# HWSEQ_L3_MAIN register map
Vendor: Texas Instruments
Peripheral module from a debugger description file (folder omap5430_ES2_PUBLIC).
Registers are 32-bit, access per field, reset 0x0 unless marked. A register's access mark holds for its fields unless they carry their own. Offsets are as the file gives them; lines under a group give offsets from that group; [hi:lo] are bit positions; {n}, {i} and the like mark numbered series; 'fields as' and 'values as' point back to an identical list; <NAME> marks a mode.

## HWSEQ_L3_MAIN
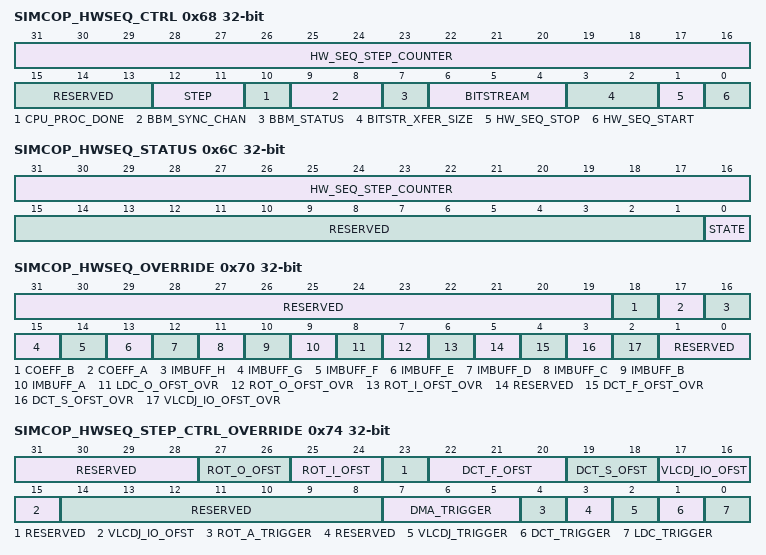
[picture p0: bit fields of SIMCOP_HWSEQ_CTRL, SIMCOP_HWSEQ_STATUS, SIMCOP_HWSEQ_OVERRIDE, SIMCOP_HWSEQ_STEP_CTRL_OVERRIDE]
0x68 SIMCOP_HWSEQ_CTRL — SIMCOP HW sequencer control register
  [31:16] HW_SEQ_STEP_COUNTER rw — Number of steps executed by the HW sequencer. HW_SEQ_STEP_COUNTER=0 corresponds to manual sequencing.
  [15:13] RESERVED ro — Read returns 0.
  [12:11] STEP rw — This register is automatically updated by the HW sequencer when it is active. Otherwise, SW could use it to activate the content of a given set of step registers (SIMCOP_HWSEQ_STEP_i).
  [10] CPU_PROC_DONE wo — Used by the CPU to tell that it has completed data processing. This feature should be used together with the CPU_PROC_START_IRQ event Read's always return 0.
    0=No_effect; 1=CPU_processing_completed
  [9:8] BBM_SYNC_CHAN rw — Defines the SIMCOP DMA HW synchronization channel to be used for BBM. This register is only used when BITSTREAM=ENCODE or DECODE. SW must ensure that the same DMA HW synchronization channel isn't used by the HW sequencer.
  [7] BBM_STATUS ro — Status of the Bitstream buffer management HW. Used only during automatic mode [BITSTREAM=5 or 6] Equals 0 (IDLE) in manual mode [BITSTREAM=0..4]. Set when automatic mode is entered. Automatic encode mode: used to detect when all banks have been flushed after the processing has completed (i.e. but request bank signals have been de-asserted by BBM). Automatic decode mode (BITSTREAM=DECODE): returns to 0 (IDLE) when automatic mode is left (BITSTREAM=COPR).
    1=BBM_is_busy; 0=BBM_is_idle
  [6:4] BITSTREAM rw — BITSTREAM buffer access control
    0=Bank 0: coprocessor bus (0x1000-0x17FF) Bank 1: coprocessor bus (0x1800-0x1FFF); 1=DMA_DMA_1 (Bank 0: DMA (0x1000-0x17FF) Bank 1: DMA (0x1800-0x1FFF)); 2=VLCDJ.B_VLCDJ.B_2 (Bank 0: VLCDJ.B (0x000-0x7FF) Bank 1: VLCDJ.B (0x800-0xFFF)); 3=DMA_VLCDJ.B_3 (Bank 0: DMA (0x1000-0x17FF) Bank 1: VLCDJ.B (0x800-0xFFF)); 4=VLCDJ.B_DMA_4 (Bank 0: VLCDJ.B (0x000-0x7FF) Bank 1: DMA (0x1800-0x1FFF)); 5=BITSTREAM_HW_PING/PONG_JPEG_SIMCOP_DMA_VLCDJ_BITSTREAM_HW_COPR,_VLCDJ_DMA._5 (The BITSTREAM buffer is managed by HW as a PING/PONG buffer to support JPEG encode use case. It could be accessed by the SIMCOP DMA or the VLCDJ module. The BITSTREAM HW sequence is reset when the mode is changed to COPR, VLCDJ or DMA.); 6=BITSTREAM_HW_PING/PONG_JPEG_SIMCOP_DMA_VLCDJ_BITSTREAM_HW_COPR,_VLCDJ_DMA._6 (The BITSTREAM buffer is managed by HW as a PING/PONG buffer to support JPEG decode use case. It could be accessed by the SIMCOP DMA or the VLCDJ module. The BITSTREAM HW sequence is reset when the mode is changed to COPR, VLCDJ or DMA.)
  [3:2] BITSTR_XFER_SIZE rw — Defines the amount of data to be transferred per HW request to the SIMCOP DMA. Bigger sizes lead to better SDRAM efficiency but prevents fine grained DMA transfer arbitration. This register is only used by HW when BITSTREAM=ENCODE or BITSTREAM=DECODE.
    0=2048_bytes; 1=1024_bytes; 2=512_bytes; 3=256_bytes
  [1] HW_SEQ_STOP wo — Stop the HW sequencer. This feature is typically used to recover from an error condition. Read's always return 0.
    0=No_effect; 1=HW_DONE_1 (Stop the HW sequence immediately (don't wait for expected DONE events). Setting this bit while the sequencer is idle has no effect.)
  [0] HW_SEQ_START wo — Start the HW sequencer. Read's always return 0.
    0=No_effect; 1=STEP0_HW_1 (Start STEP0 of the HW sequence. Setting this bit while the sequencer is running has no effect.)
0x6C SIMCOP_HWSEQ_STATUS ro — HW sequencer status register
  [31:16] HW_SEQ_STEP_COUNTER — Current step number
  [15:1] RESERVED — Read returns 0.
  [0] STATE — Current state
    0=Idle; 1=Running
0x70 SIMCOP_HWSEQ_OVERRIDE — HW sequencer override control register. Bits in this register select what configuration register control a resource. 0: Resource controlled by HW sequencer. HW uses the value from SIMCOP_HWSEQ_STEP_xx registers for the chosen resource 1: Resource controlled by SW HW uses the value from SIMCOP_HWSEQ_STEP_x_OVERRIDE registers for the chosen resource The bit field name matches the one of the resource.
  [31:19] RESERVED ro — Read returns 0.
  [18] COEFF_B rw — See register description
  [17] COEFF_A rw — See register description
  [16] IMBUFF_H rw — See register description
  [15] IMBUFF_G rw — See register description
  [14] IMBUFF_F rw — See register description
  [13] IMBUFF_E rw — See register description
  [12] IMBUFF_D rw — See register description
  [11] IMBUFF_C rw — See register description
  [10] IMBUFF_B rw — See register description
  [9] IMBUFF_A rw — See register description
  [8] LDC_O_OFST_OVR rw — See register description
  [7] ROT_O_OFST_OVR rw — See register description
  [6] ROT_I_OFST_OVR rw — See register description
  [5] RESERVED ro — Read returns 0.
  [4] DCT_F_OFST_OVR rw — See register description
  [3] DCT_S_OFST_OVR rw — See register description
  [2] VLCDJ_IO_OFST_OVR rw — See register description
  [1:0] RESERVED ro — Read returns 0.
0x74 SIMCOP_HWSEQ_STEP_CTRL_OVERRIDE — HW sequencer override register. Used to execute SW sequences in parallel to HW sequencing steps
  [31:28] RESERVED ro — Read returns 0.
  [27:26] ROT_O_OFST rw — Controls ROT.O bus mapping to image buffers: 0x0000 0x1000 0x2000 0x3000
    0=EFGH; 1=FGHE; 2=GHEF; 3=HEFG
  [25:24] ROT_I_OFST rw — Controls ROT_I bus mapping to image buffers: 0x0000 0x1000 0x2000 0x3000
    0=ABCD; 1=BCDA; 2=CDAB; 3=DABC
  [23] RESERVED ro — Read returns 0.
  [22:20] DCT_F_OFST rw — Controls DCT.F bus mapping to image buffers: 0x0000 0x1000 0x2000 0x3000
    0=ABCD; 1=BCDG; 2=CDGH; 3=DGHA; 4=GHAB; 5=HABC
  [19:18] DCT_S_OFST rw — Controls DCT.S bus mapping to image buffers: 0x0000 0x1000
    0=EF; 1=FG; 2=GH; 3=HE
  [17:15] VLCDJ_IO_OFST rw — Controls VLCDJ IO data bus mapping to image buffers: 0x0000 0x1000 0x2000 0x3000
    0=ABCD; 1=BCDG; 2=CDGH; 3=DGHA; 4=GHAB; 5=HABC
  [14:8] RESERVED ro — Read returns 0.
  [7:5] DMA_TRIGGER rw — SW controlled START/DONE synchronization
    0=No_effect; 0=No done pulse have been received since last non zero write into the DMA_TRIGGER register; 1=DONE_1 (DONE pulses for channel 0 and 1 have been received); 1=DMA._1 (Trigger channel 0 and 1. Clears all memorized done pulses for DMA.); 2=DMA._2 (Trigger channel 0, 1, 2. Clears all memorized done pulses for DMA.); 2=DONE_2 (DONE pulses for channel 0, 1 and 2 have been received); 3=DONE_3 (DONE pulses for channel 0, 1, 2 and 3 have been received.); 3=DMA._3 (Trigger channel 0, 1, 2 and 3. Clears all memorized done pulses for DMA.); {v}=DONE_{v} (DONE pulse for channel {v-4} has been received) (v=4..7); {v}=DMA._{v} (Trigger channel {v-4}. Clears all memorized done pulses for DMA.) (v=4..7)
  [4] ROT_A_TRIGGER rw — SW controlled START/DONE synchronization
    0=No_Effect; 0=DONE_START_0 (No DONE pulse received since the last START pulse has been sent); 1=DONE_pulse_received; 1=ROT_A_TRIGGER_1_w (Send a start pulse and clears the memorized done pulse)
  [3] RESERVED ro — Read returns 0.
  [2] VLCDJ_TRIGGER rw — SW controlled START/DONE synchronization
    0=No_Effect; 0=DONE_START_0 (No DONE pulse received since the last START pulse has been sent); 1=DONE_pulse_received; 1=VLCDJ_TRIGGER_1_w (Send a start pulse and clears the memorized done pulse)
  [1] DCT_TRIGGER rw — SW controlled START/DONE synchronization
    0=No_Effect; 0=DONE_START_0 (No DONE pulse received since the last START pulse has been sent); 1=DONE_pulse_received; 1=DCT_TRIGGER_1_w (Send a start pulse and clears the memorized done pulse)
  [0] LDC_TRIGGER rw — SW controlled START/DONE synchronization
    0=No_Effect; 0=DONE_START_0 (No DONE pulse received since the last START pulse has been sent); 1=DONE_pulse_received; 1=LDC_TRIGGER_1_w (Send a start pulse and clears the memorized done pulse)
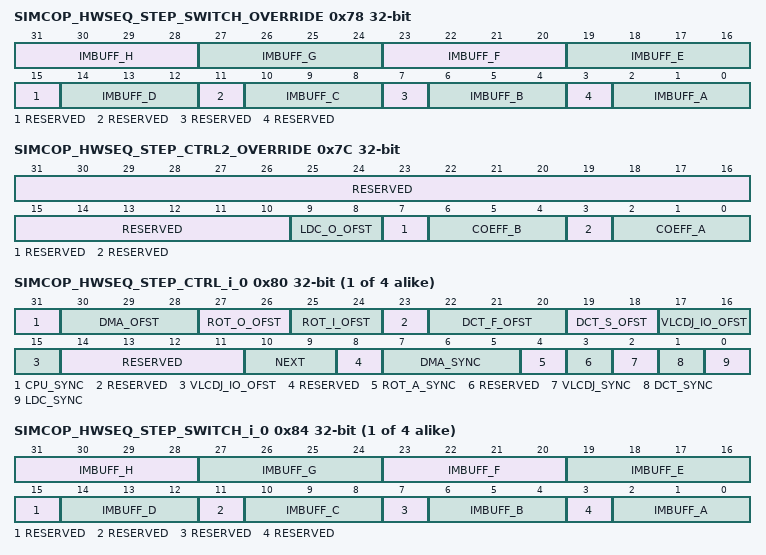
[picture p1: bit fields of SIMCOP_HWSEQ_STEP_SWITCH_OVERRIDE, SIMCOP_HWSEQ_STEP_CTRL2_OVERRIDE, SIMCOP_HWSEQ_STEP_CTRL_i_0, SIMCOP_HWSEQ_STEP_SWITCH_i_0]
0x78 SIMCOP_HWSEQ_STEP_SWITCH_OVERRIDE — HW sequencer override register. Used to execute SW sequences in parallel to HW sequencing steps
  [31:28] IMBUFF_H rw — Switch for image buffer h
    0=Coprocessor_bus; 1=SIMCOP_DMA; 4=VLCDJ_IO; 5=DCT_S; 6=DCT_F; 7=ROT_A_O; 9=LDC_O
  [27:24] IMBUFF_G rw — Switch for image buffer g
    values as IMBUFF_H
  [23:20] IMBUFF_F rw — Switch for image buffer f
    0=Coprocessor_bus; 1=SIMCOP_DMA; 4=DCT_S; 6=LDC_O; 7=ROT_A_O
  [19:16] IMBUFF_E rw — Switch for image buffer e
    0=Coprocessor_bus; 1=SIMCOP_DMA; 4=DCT_S; 6=LDC_O; 7=ROT_A_O
  [15] RESERVED ro — Read returns 0.
  [14:12] IMBUFF_D rw — Switch for image buffer d
    0=Coprocessor_bus; 1=SIMCOP_DMA; 4=VLCDJ_IO; 5=DCT_F; 6=ROT_A_I
  [11] RESERVED ro — Read returns 0.
  [10:8] IMBUFF_C rw — Switch for image buffer c
    values as IMBUFF_D
  [7] RESERVED ro — Read returns 0.
  [6:4] IMBUFF_B rw — Switch for image buffer b
    values as IMBUFF_D
  [3] RESERVED ro — Read returns 0.
  [2:0] IMBUFF_A rw — Switch for image buffer a
    values as IMBUFF_D
0x7C SIMCOP_HWSEQ_STEP_CTRL2_OVERRIDE — HW sequencer override register. Used to execute SW sequences in parallel to HW sequencing steps
  [31:10] RESERVED ro — Read returns 0.
  [9:8] LDC_O_OFST rw — Controls LDC.O bus mapping to image buffers: 0x0000 0x1000 0x2000 0x3000
    0=EFGH; 1=FGHE; 2=GHEF; 3=HEFG
  [7] RESERVED ro — Read returns 0.
  [6:4] COEFF_B rw — Coefficient buffer B switch
    0=Coprocessor_bus; 1=SIMCOP_DMA; 2=IMX_A; 3=IMX_B; 4=VLCDJ_IO; 5=DCT_F; 6=ROT_A_O
  [3] RESERVED ro — Read returns 0.
  [2:0] COEFF_A rw — Coefficient buffer a switch
    0=Coprocessor_bus; 1=SIMCOP_DMA; 2=IMX_A; 3=IMX_B; 4=VLCDJ_IO; 5=DCT_F; 6=ROT_A_I
{0x80+0x10*i} SIMCOP_HWSEQ_STEP_CTRL_i_{i} (i=0..3) — HW sequencer step control register
  [31] CPU_SYNC rw — Enable HW synchronization with the CPU so that it could be used for some processing on in the macro-block pipeline.
    0=Disabled; 1=Enabled
  [30:28] DMA_OFST rw — Controls DMA bus mapping to image buffers: 0x0000 0x1000 0x2000 0x3000 0x4000 0x5000 0x6000 0x7000
    0=ABCDEFGH; 1=BCDEFGHA; 2=CDEFGHAB; 3=DEFGHABC; 4=EFGHABCD; 5=FGHABCDE; 6=GHABCDEF; 7=HABCDEFG
  [27:26] ROT_O_OFST rw — Controls ROT.O bus mapping to image buffers: 0x0000 0x1000 0x2000 0x3000
    0=EFGH; 1=FGHE; 2=GHEF; 3=HEFG
  [25:24] ROT_I_OFST rw — Controls ROT_I bus mapping to image buffers: 0x0000 0x1000 0x2000 0x3000
    0=ABCD; 1=BCDA; 2=CDAB; 3=DABC
  [23] RESERVED ro — Read returns 0.
  [22:20] DCT_F_OFST rw — Controls DCT.F bus mapping to image buffers: 0x0000 0x1000 0x2000 0x3000
    0=ABCD; 1=BCDG; 2=CDGH; 3=DGHA; 4=GHAB; 5=HABC
  [19:18] DCT_S_OFST rw — Controls DCT.S bus mapping to image buffers: 0x0000 0x1000
    0=EF; 1=FG; 2=GH; 3=HE
  [17:15] VLCDJ_IO_OFST rw — Controls VLCDJ IO data bus mapping to image buffers: 0x0000 0x1000 0x2000 0x3000
    0=ABCD; 1=BCDG; 2=CDGH; 3=DGHA; 4=GHAB; 5=HABC
  [14:11] RESERVED ro — Read returns 0.
  [10:9] NEXT rw — Next channel in the sync chain
    {v}=Step_{v} (v=0..3)
  [8] RESERVED ro — Read returns 0.
  [7:5] DMA_SYNC rw — Enable HW synchronization with the SIMCOP DMA
    0=Disabled; 1=Channel_0_and_1; 2=Channel_0,_1,_2; 3=Channel_0,_1,_2_and_3; {v}=Channel_{v-4} (v=4..7)
  [4] ROT_A_SYNC rw — Enable HW synchronization with the ROT A module
    0=Disabled; 1=Enabled
  [3] RESERVED ro — Read returns 0.
  [2] VLCDJ_SYNC rw — Enable HW synchronization with the VLCDJ module
    0=Disabled; 1=Enabled
  [1] DCT_SYNC rw — Enable HW synchronization with the DCT module
    0=Disabled; 1=Enabled
  [0] LDC_SYNC rw — Enable HW synchronization with the LDC module
    0=Disabled; 1=Enabled
{0x84+0x10*i} SIMCOP_HWSEQ_STEP_SWITCH_i_{i} (i=0..3) — Image buffer switch control. The configuration of Step 0 is used when HW sequencer is idle.
  fields as SIMCOP_HWSEQ_STEP_SWITCH_OVERRIDE
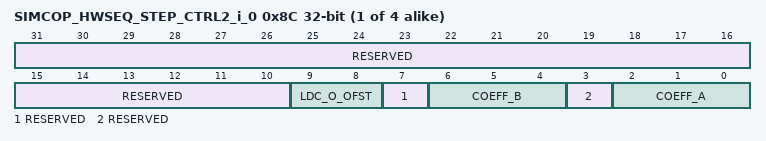
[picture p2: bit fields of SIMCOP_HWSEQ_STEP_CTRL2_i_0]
{0x8C+0x10*i} SIMCOP_HWSEQ_STEP_CTRL2_i_{i} (i=0..3) — HW sequencer step control register
  [31:10] RESERVED ro — Read returns 0.
  [9:8] LDC_O_OFST rw — Controls LDC.O bus mapping to image buffers: 0x0000 0x1000 0x2000 0x3000
    0=EFGH; 1=FGHE; 2=GHEF; 3=HEFG
  [7] RESERVED ro — Read returns 0.
  [6:4] COEFF_B rw — Coefficient buffer b switch
    values as SIMCOP_HWSEQ_STEP_CTRL2_OVERRIDE.COEFF_B
  [3] RESERVED ro — Read returns 0.
  [2:0] COEFF_A rw — Coefficient buffer a switch
    values as SIMCOP_HWSEQ_STEP_CTRL2_OVERRIDE.COEFF_A
